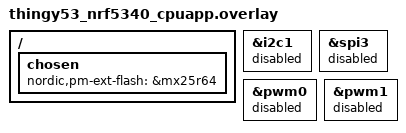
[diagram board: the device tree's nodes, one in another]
/*
 * Copyright (c) 2022 Nordic Semiconductor ASA
 *
 * SPDX-License-Identifier: LicenseRef-Nordic-5-Clause
 */

 / {
	chosen {
		nordic,pm-ext-flash = &mx25r64;
	};
};

/* Disable unused peripherals to reduce power consumption */
&i2c1 {
	status = "disabled";
};
&spi3 {
	status = "disabled";
};
&pwm0 {
	status = "disabled";
};
&pwm1 {
	status = "disabled";
};
